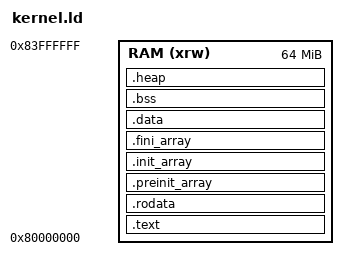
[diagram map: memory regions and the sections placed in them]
/* Specify the memory areas */
MEMORY
{
	RAM(xrw): ORIGIN = 0x80000000, LENGTH = 0x04000000
}

/* Entry Point */
ENTRY(entry)

/* Highest address of the user mode stack */
__stack_end__ = 0x20010000;     /* end of DTCM */
__heap_size__ = 16 * 1024;      /* Heap size 16k */

/* Define output sections */
SECTIONS
{
  /* The program code and other data goes into TEXT */
  .text :
  {
    . = ALIGN(4);
    *(.text)           /* .text sections (code) */
    *(.text*)          /* .text* sections (code) */
    *(.glue_7)         /* glue arm to thumb code */
    *(.glue_7t)        /* glue thumb to arm code */
    *(.eh_frame)

    KEEP(*(.init))
    KEEP(*(.fini))

    . = ALIGN(4);
    _etext = .;        /* define a global symbols at end of code */
  } >RAM

  /* Constant data goes into TEXT */
  .rodata :
  {
    . = ALIGN(4);
    *(.rodata)         /* .rodata sections (constants, strings, etc.) */
    *(.rodata*)        /* .rodata* sections (constants, strings, etc.) */

    . = ALIGN(4);
  } >RAM

  .preinit_array     :
  {
    PROVIDE_HIDDEN (__preinit_array_start = .);
    KEEP(*(.preinit_array*))
    PROVIDE_HIDDEN (__preinit_array_end = .);
  } >RAM
  .init_array :
  {
    PROVIDE_HIDDEN (__init_array_start = .);
    KEEP(*(SORT(.init_array.*)))
    KEEP(*(.init_array*))
    PROVIDE_HIDDEN (__init_array_end = .);
  } >RAM
  .fini_array :
  {
    PROVIDE_HIDDEN (__fini_array_start = .);
    KEEP(*(SORT(.fini_array.*)))
    KEEP(*(.fini_array*))
    PROVIDE_HIDDEN (__fini_array_end = .);
  } >RAM

  /* Initialized data sections goes into RAM, load LMA copy after code */
  . = ALIGN(4);
  /* used by the startup to initialize data */
  __data_load__ = LOADADDR(.data);

  .data :
  {
    __data_start__ = .;
    . = ALIGN(4);
    *(.data)           /* .data sections */
    *(.data*)          /* .data* sections */
    /* Special program code inside RAM */
    *(.ram)
    *(.ram*)

    . = ALIGN(4);
    __data_end__ = .;
  } >RAM

  /* Uninitialized data section */
  . = ALIGN(4);
  .bss (NOLOAD) :
  {
    /* This is used by the startup in order to initialize the .bss secion */
    __bss_start__ = .;
    *(.bss)
    *(.bss*)
    *(COMMON)

    . = ALIGN(4);
    __bss_end__ = .;
  } >RAM

  /* Heap section */
  . = ALIGN(4);
  .heap :
  {
    . = ALIGN(4);
    __heap_start__ = .;
    /* Reserve space */
    . += __heap_size__;
    . = ALIGN(4);
    __heap_end__ = .;
  } >RAM

  /* Remove information from the standard libraries */
  /DISCARD/ :
  {
    libc.a ( * )
    libm.a ( * )
    libgcc.a ( * )
    *(.olist.*)
  }
}
